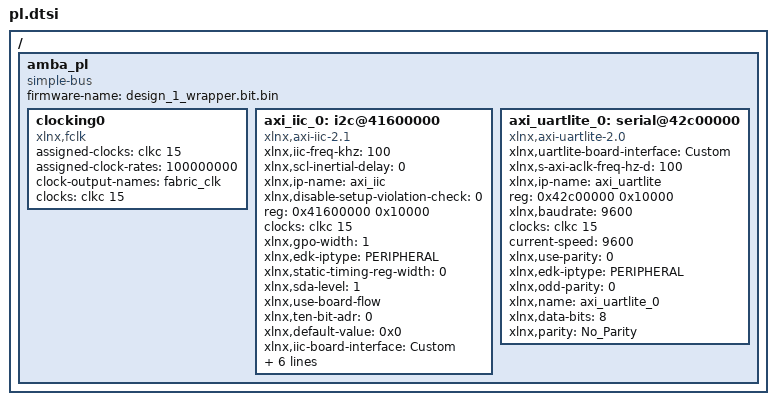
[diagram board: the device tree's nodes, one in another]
/ {
	amba_pl: amba_pl {
		ranges;
		compatible = "simple-bus";
		#address-cells = <1>;
		#size-cells = <1>;
		firmware-name = "design_1_wrapper.bit.bin";
		clocking0: clocking0 {
			compatible = "xlnx,fclk";
			assigned-clocks = <&clkc 15>;
			assigned-clock-rates = <100000000>;
			#clock-cells = <0>;
			clock-output-names = "fabric_clk";
			clocks = <&clkc 15>;
		};
		axi_iic_0: i2c@41600000 {
			xlnx,iic-freq-khz = <100>;
			compatible = "xlnx,axi-iic-2.1" , "xlnx,xps-iic-2.00.a";
			xlnx,scl-inertial-delay = <0>;
			xlnx,ip-name = "axi_iic";
			xlnx,disable-setup-violation-check = <0>;
			reg = <0x41600000 0x10000>;
			clocks = <&clkc 15>;
			xlnx,gpo-width = <1>;
			xlnx,edk-iptype = "PERIPHERAL";
			xlnx,static-timing-reg-width = <0>;
			xlnx,sda-level = <1>;
			status = "okay";
			clock-names = "s_axi_aclk";
			xlnx,use-board-flow;
			xlnx,ten-bit-adr = <0>;
			xlnx,default-value = <0x0>;
			xlnx,iic-board-interface = "Custom";
			xlnx,timing-reg-width = <32>;
			xlnx,iic-freq = <100000>;
			xlnx,smbus-pmbus-host = <0>;
			xlnx,name = "axi_iic_0";
			xlnx,axi-aclk-freq-mhz = <100>;
			xlnx,sda-inertial-delay = <0>;
		};
		axi_uartlite_0: serial@42c00000 {
			compatible = "xlnx,axi-uartlite-2.0" , "xlnx,xps-uartlite-1.00.a";
			xlnx,uartlite-board-interface = "Custom";
			xlnx,s-axi-aclk-freq-hz-d = <100>;
			xlnx,ip-name = "axi_uartlite";
			reg = <0x42c00000 0x10000>;
			xlnx,baudrate = <9600>;
			clocks = <&clkc 15>;
			current-speed = <9600>;
			xlnx,use-parity = <0>;
			xlnx,edk-iptype = "PERIPHERAL";
			xlnx,odd-parity = <0>;
			status = "okay";
			clock-names = "s_axi_aclk";
			xlnx,name = "axi_uartlite_0";
			xlnx,data-bits = <8>;
			xlnx,parity = "No_Parity";
		};
	};
};
